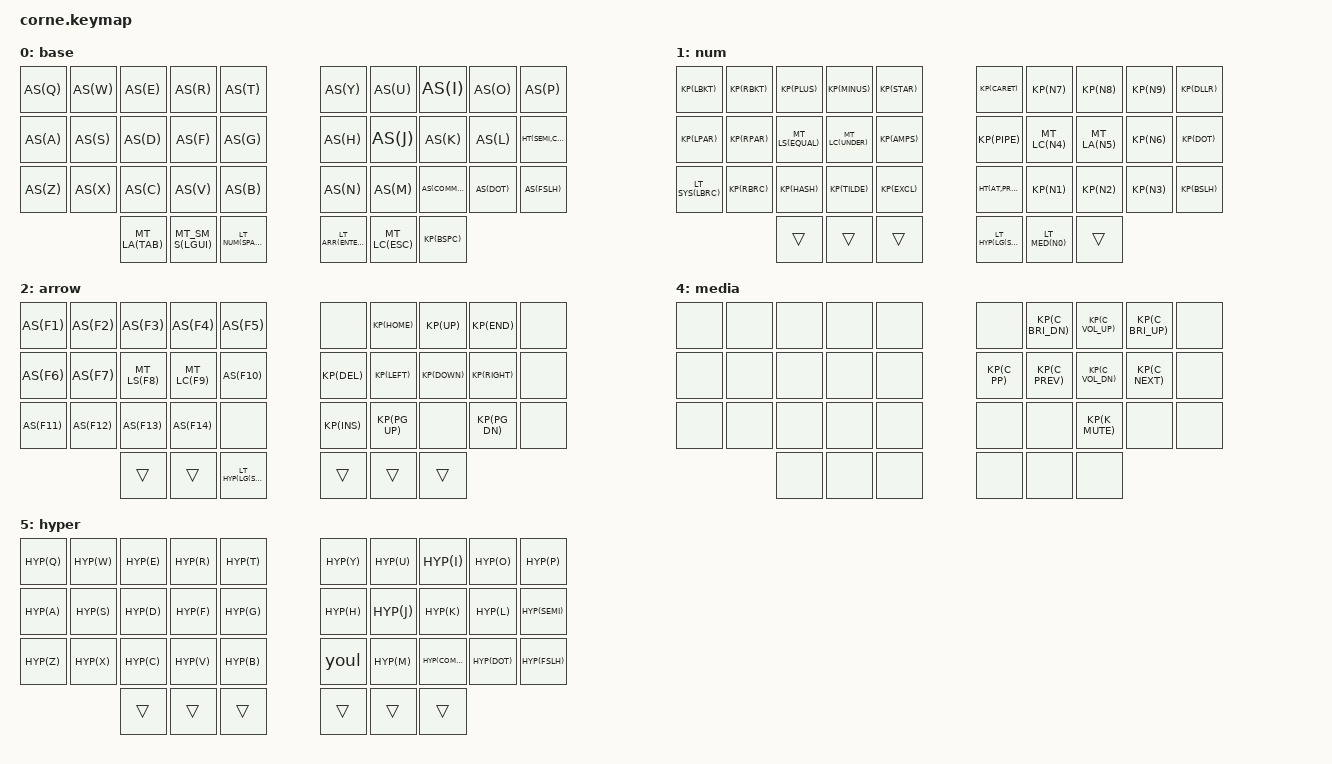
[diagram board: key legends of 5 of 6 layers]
#include <behaviors.dtsi>
#include <dt-bindings/zmk/keys.h>
#include <dt-bindings/zmk/outputs.h>
#include <dt-bindings/zmk/bt.h>

#include "./zmk-nodefree-config/helper.h"
#include "./zmk-nodefree-config/keypos_def/keypos_36keys.h"

#define BASE 0
#define NUM 1
#define ARROW 2
#define SYS 3
#define MEDIA 4
#define HYPER 5

/* Global settings */

&sk {  // sticky-key config
    release-after-ms = <3000>;
    quick-release;             // no double capitalization when rolling keys
};

&lt {
    flavor = "hold-preferred";
};

&caps_word {
    /delete-property/ ignore-modifiers;
};

&led_strip {
    // chain-length = <21>;
};

&nice_view_spi {
    // cs-gpios = <&pro_micro 0 GPIO_ACTIVE_HIGH>;
};

// ZMK_CONDITIONAL_LAYER(1 0, 0)

/ {
    chosen {
        zmk,matrix_transform = &five_column_transform;
    };
};

ZMK_BEHAVIOR(tap, macro_one_param,
    bindings = 
      <&macro_param_1to1>,
      <&kp MACRO_PLACEHOLDER>;
)

ZMK_BEHAVIOR(youl, macro, bindings = <&kp Y &kp O &kp U &kp L &kp I &kp N &kp G>;)

#define MAKE_HT(name, hold_bind, tap_bind) \
    ZMK_BEHAVIOR(name, hold_tap, \
        flavor = "tap-preferred"; \
        tapping-term-ms = <200>; \
        require-prior-idle-ms = <125>; \
        bindings = <hold_bind>, <tap_bind>; \
    )

#define MAKE_MT(name, hold_bind, tap_bind) \
    ZMK_BEHAVIOR(name, hold_tap, \
        flavor = "hold-preferred"; \
        tapping-term-ms = <200>; \
        bindings = <hold_bind>, <tap_bind>; \
    )

MAKE_HT(ht, &tap, &kp)
MAKE_MT(mt_smart_shft, &kp, &smart_shft)

#define MAKE_HT_PAIR(NAME, L_KEY, R_KEY) \
    ZMK_BEHAVIOR(p_ ## NAME, macro, bindings = <&kp L_KEY &kp R_KEY &kp LEFT>;) \
    MAKE_HT(ht_ ## NAME, &p_ ## NAME, &kp)

MAKE_HT_PAIR(bkt, LBKT, RBKT)
MAKE_HT_PAIR(brc, LBRC, RBRC)
MAKE_HT_PAIR(par, LPAR, RPAR)
MAKE_HT_PAIR(sqt, SQT, SQT)
MAKE_HT_PAIR(dqt, DQT, DQT)
MAKE_HT_PAIR(gra, GRAVE, GRAVE)

#define HT_BKT &ht_bkt 0 LBKT
#define HT_BRC &ht_brc 0 LBRC
#define HT_PAR &ht_par 0 LPAR
#define HT_SQT &ht_sqt 0 SQT
#define HT_DQT &ht_dqt 0 DQT
#define HT_GRA &ht_gra 0 GRAVE

ZMK_BEHAVIOR(p_ltgt, macro, bindings = <&kp LT &kp GT &kp LEFT>;)

// tap: sticky-shift | shift + tap/ double-tap: caps-word | hold: shift
ZMK_BEHAVIOR(smart_shft, mod_morph,
    bindings = <&sk LSHFT>, <&caps_word>;
    mods = <(MOD_LSFT)>;
)

/*                KEY POSITIONS

  ╭─────────────────────╮ ╭─────────────────────╮
  │ LT4 LT3 LT2 LT1 LT0 │ │ RT0 RT1 RT2 RT3 RT4 │
  │ LM4 LM3 LM2 LM1 LM0 │ │ RM0 RM1 RM2 RM3 RM4 │
  │ LB4 LB3 LB2 LB1 LB0 │ │ RB0 RB1 RB2 RB3 RB4 │
  ╰───────╮ LH2 LH1 LH0 │ │ RH0 RH1 RH2 ╭───────╯
          ╰─────────────╯ ╰─────────────╯ */

// use require-prior-idle-ms for combos
#undef COMBO_HOOK
#define COMBO_HOOK require-prior-idle-ms = <150>;

#undef COMBO_TERM
#define COMBO_TERM 20

ZMK_COMBO(bkt, HT_BKT, RT1 RT2, BASE)
ZMK_COMBO(par, HT_PAR, RM1 RM2, BASE)
ZMK_COMBO(brc, HT_BRC, RB1 RB2, BASE)
ZMK_COMBO(sqt, HT_SQT, LT1 LT2, BASE)
ZMK_COMBO(dqt, HT_DQT, LM1 LM2, BASE)
ZMK_COMBO(gra, HT_GRA, LB1 LB2, BASE)
ZMK_COMBO(ltgt, &p_ltgt, RB2 RB3, BASE, 50)

#define XXX &none
#define ___ &trans
#define AS(key) &ht LS(key) key
#define KP(key) &kp key
#define MT(mod_key,tap_key) &mt mod_key tap_key
#define HT(hold_key,tap_key) &ht hold_key tap_key
#define MT_LS(tap_key) &mt LSHFT tap_key
#define MT_LG(tap_key) &mt LGUI tap_key
#define MT_LC(tap_key) &mt LCTRL tap_key
#define MT_LA(tap_key) &mt LALT tap_key
#define LT_NUM(tap_key) &lt NUM tap_key
#define LT_ARR(tap_key) &lt ARROW tap_key
#define LT_SYS(tap_key) &lt SYS tap_key
#define LT_MED(tap_key) &lt MEDIA tap_key
#define LT_HYP(tap_key) &lt HYPER tap_key
#define MT_SM_S(mod_key) &mt_smart_shft mod_key 0

ZMK_LAYER(base,
    AS(Q) AS(W) AS(E) AS(R) AS(T)            AS(Y) AS(U) AS(I) AS(O) AS(P)
    AS(A) AS(S) AS(D) AS(F) AS(G)            AS(H) AS(J) AS(K) AS(L) HT(SEMI,COLON)
    AS(Z) AS(X) AS(C) AS(V) AS(B)            AS(N) AS(M) AS(COMMA) AS(DOT) AS(FSLH)
    MT_LA(TAB) MT_SM_S(LGUI) LT_NUM(SPACE)   LT_ARR(ENTER) MT_LC(ESC) KP(BSPC)
)

ZMK_LAYER(num,
    KP(LBKT) KP(RBKT) KP(PLUS) KP(MINUS) KP(STAR)          KP(CARET) KP(N7) KP(N8) KP(N9) KP(DLLR)
    KP(LPAR) KP(RPAR) MT_LS(EQUAL) MT_LC(UNDER) KP(AMPS)   KP(PIPE) MT_LC(N4) MT_LA(N5) KP(N6) KP(DOT)
    LT_SYS(LBRC) KP(RBRC) KP(HASH) KP(TILDE) KP(EXCL)      HT(AT,PRCNT) KP(N1) KP(N2) KP(N3) KP(BSLH)
    ___ ___ ___                                            LT_HYP(LG(SPACE)) LT_MED(N0) ___
)

ZMK_LAYER(arrow,
    AS(F1) AS(F2) AS(F3) AS(F4) AS(F5)          XXX KP(HOME) KP(UP) KP(END) XXX
    AS(F6) AS(F7) MT_LS(F8) MT_LC(F9) AS(F10)   KP(DEL) KP(LEFT) KP(DOWN) KP(RIGHT) XXX
    AS(F11) AS(F12) AS(F13) AS(F14) XXX         KP(INS) KP(PG_UP) XXX KP(PG_DN) XXX
    ___ ___ LT_HYP(LG(SPACE))                   ___ ___ ___
)

#define _BT_SEL_KEYS_ &bt BT_SEL 0 &bt BT_SEL 1 &bt BT_SEL 2 &bt BT_SEL 3 &bt BT_CLR

ZMK_LAYER(sys,
    _BT_SEL_KEYS_                         XXX KP(C_BRI_DN) KP(C_VOL_UP) KP(C_BRI_UP) XXX
    XXX XXX XXX XXX XXX                   KP(C_PP) KP(C_PREV) KP(C_VOL_DN) KP(C_NEXT) XXX
    XXX XXX XXX XXX XXX                   XXX XXX KP(K_MUTE) XXX XXX
    &out OUT_TOG &sys_reset &bootloader   &bootloader &sys_reset &soft_off
)

ZMK_LAYER(media,
    XXX XXX XXX XXX XXX   XXX KP(C_BRI_DN) KP(C_VOL_UP) KP(C_BRI_UP) XXX
    XXX XXX XXX XXX XXX   KP(C_PP) KP(C_PREV) KP(C_VOL_DN) KP(C_NEXT) XXX
    XXX XXX XXX XXX XXX   XXX XXX KP(K_MUTE) XXX XXX
    XXX XXX XXX           XXX XXX XXX
)

#define HYP(key) AS(RG(RA(RC(key))))

ZMK_LAYER(hyper,
    HYP(Q) HYP(W) HYP(E) HYP(R) HYP(T)   HYP(Y) HYP(U) HYP(I) HYP(O) HYP(P)
    HYP(A) HYP(S) HYP(D) HYP(F) HYP(G)   HYP(H) HYP(J) HYP(K) HYP(L) HYP(SEMI)
    HYP(Z) HYP(X) HYP(C) HYP(V) HYP(B)   &youl HYP(M) HYP(COMMA) HYP(DOT) HYP(FSLH)
    ___ ___ ___                          ___ ___ ___
)

